# STM32WB07 register map
File version: 1.0
CPU: CM0+ r0p0, little endian, MPU, no FPU, 2 interrupt priority bits
Registers are 32-bit, read-write, reset 0x0 unless marked. A register's access mark holds for its fields unless they carry their own. Offsets are from the block's base; [hi:lo] are bit positions; {n}, {i} and the like mark numbered series; 'fields as' and 'values as' point back to an identical list.

## TIM1
Base 0x40002000
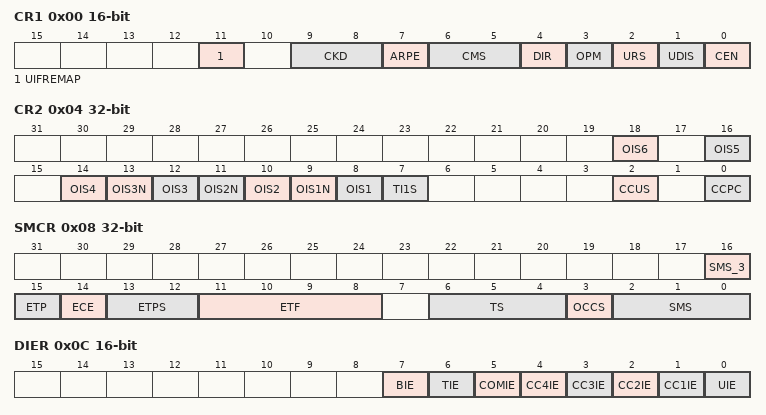
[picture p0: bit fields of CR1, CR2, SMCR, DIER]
0x00 CR1 16-bit (reset mask 0xF)
  [11] UIFREMAP — UIFREMAP: UIF status bit remapping 0: No remapping. UIF status bit is not copied to TIMx_CNT register bit 31. 1: Remapping enabled. UIF status bit is copied to TIMx_CNT register bit 31.
  [9:8] CKD — CKD[1:0]: Clock division This bit-field indicates the division ratio between the timer clock (CK_INT) frequency and the dead-time and sampling clock (tDTS)used by the dead-time generators and the digital filters (TIx), 00: tDTS=tCK_INT 01: tDTS=2*tCK_INT 10: tDTS=4*tCK_INT 11: Reserved, do not program this value
    0=Div1 (t_DTS = t_CK_INT); 1=Div2 (t_DTS = 2 × t_CK_INT); 2=Div4 (t_DTS = 4 × t_CK_INT)
  [7] ARPE — ARPE: Auto-reload preload enable 0: TIMx_ARR register is not buffered 1: TIMx_ARR register is buffered
    0=Disabled (TIMx_APRR register is not buffered); 1=Enabled (TIMx_APRR register is buffered)
  [6:5] CMS — CMS[1:0]: Center-aligned mode selection 00: Edge-aligned mode. The counter counts up or down depending on the direction bit (DIR). 01: Center-aligned mode 1. The counter counts up and down alternatively. Output compare interrupt flags of channels configured in output (CCxS=00 in TIMx_CCMRx register) are set only when the counter is counting down. 10: Center-aligned mode 2. The counter counts up and down alternatively. Output compare interrupt flags of channels configured in output (CCxS=00 in TIMx_CCMRx register) are set only when the counter is counting up. 11: Center-aligned mode 3. The counter counts up and down alternatively. Output compare interrupt flags of channels configured in output (CCxS=00 in TIMx_CCMRx register) are set both when the counter is counting up or down. Note: It is not allowed to switch from edge-aligned mode to center-aligned mode as long as the counter is enabled (CEN=1)
    0=EdgeAligned (The counter counts up or down depending on the direction bit); 1=CenterAligned1 (The counter counts up and down alternatively. Output compare interrupt flags are set only when the counter is counting down.); 2=CenterAligned2 (The counter counts up and down alternatively. Output compare interrupt flags are set only when the counter is counting up.); 3=CenterAligned3 (The counter counts up and down alternatively. Output compare interrupt flags are set both when the counter is counting up or down.)
  [4] DIR — DIR: Direction 0: Counter used as upcounter 1: Counter used as downcounter Note: This bit is read only when the timer is configured in Center-aligned mode or Encoder mode.
    0=Up (Counter used as upcounter); 1=Down (Counter used as downcounter)
  [3] OPM — OPM: One pulse mode 0: Counter is not stopped at update event. 1: Counter stops counting at the next update event (clearing the bit CEN)
    0=Disabled (Counter is not stopped at update event); 1=Enabled (Counter stops counting at the next update event (clearing the CEN bit))
  [2] URS — URS: Update request source This bit is set and cleared by software to select the UEV event sources. 0: Any of the following events generate an update interrupt or DMA request if enabled. These events can be: - Counter overflow/underflow - Setting the UG bit - Update generation through the slave mode controller 1: Only counter overflow/underflow generates an update interrupt or DMA request if enabled.
    0=AnyEvent (Any of counter overflow/underflow, setting UG, or update through slave mode, generates an update interrupt or DMA request); 1=CounterOnly (Only counter overflow/underflow generates an update interrupt or DMA request)
  [1] UDIS — UDIS: Update disable This bit is set and cleared by software to enable/disable UEV event generation. 0: UEV enabled. The Update (UEV) event is generated by one of the following events: - Counter overflow/underflow - Setting the UG bit - Update generation through the slave mode controller Buffered registers are then loaded with their preload values. 1: UEV disabled. The Update event is not generated, shadow registers keep their value (ARR, PSC, CCRx). However the counter and the prescaler are reinitialized if the UG bit is set or if a hardware reset is received from the slave mode controller.
    0=Enabled (Update event enabled); 1=Disabled (Update event disabled)
  [0] CEN — CEN: Counter enable 0: Counter disabled 1: Counter enabled Note: External clock and gated mode can work only if the CEN bit has been previously set by software. However trigger mode can set the CEN bit automatically by hardware.
    0=Disabled (Counter disabled); 1=Enabled (Counter enabled)
0x04 CR2 (reset mask 0xF)
  [2n+7] OIS{n}N (n=1..3) — Output Idle state (OC{n}N output)
    0=Reset (OCxN=0 after a dead-time when MOE=0); 1=Set (OCxN=1 after a dead-time when MOE=0)
  [2n+6] OIS{n} (n=1..6) — Output Idle state (OC{n} output)
    0=Reset (OCx=0 (after a dead-time if OCx(N) is implemented) when MOE=0); 1=Set (OCx=1 (after a dead-time if OCx(N) is implemented) when MOE=0)
  [7] TI1S — TI1S: TI1 selection 0: The TIMx_CH1 pin is connected to TI1 input. 1: The TIMx_CH1, CH2 and CH3 pins are connected to the TI1 input (XOR combination)
  [2] CCUS — Capture/compare control update selection.
    0=Sw (When capture/compare control bits are preloaded (CCPC=1), they are updated by setting the COMG bit only); 1=SwOrEdge (When capture/compare control bits are preloaded (CCPC=1), they are updated by setting the COMG bit or when an rising edge occurs on TRGI)
  [0] CCPC — Capture/compare preloaded control.
    0=NotPreloaded (CCxE, CCxNE and OCxM bits are not preloaded); 1=Preloaded (CCxE, CCxNE and OCxM bits are preloaded)
0x08 SMCR reset not defined
  [16] SMS_3 — SMS[3]: Slave mode selection - bit 3 Refer to SMS description - bits2:0
  [15] ETP — ETP: External trigger polarity This bit selects whether ETR or ETR is used for trigger operations 0: ETR is non-inverted, active at high level or rising edge. 1: ETR is inverted, active at low level or falling edge.
    0=NotInverted (ETR is noninverted, active at high level or rising edge); 1=Inverted (ETR is inverted, active at low level or falling edge)
  [14] ECE — ECE: External clock enable This bit enables External clock mode 2. 0: External clock mode 2 disabled 1: External clock mode 2 enabled. The counter is clocked by any active edge on the ETRF signal. Note: 1: Setting the ECE bit has the same effect as selecting external clock mode 1 with TRGI connected to ETRF (SMS=111 and TS=111). Note: 2: It is possible to simultaneously use external clock mode 2 with the following slave modes: reset mode, gated mode and trigger mode. Nevertheless, TRGI must not be connected to ETRF in this case (TS bits must not be 111). Note: 3: If external clock mode 1 and external clock mode 2 are enabled at the same time, the external clock input is ETRF.
    0=Disabled (External clock mode 2 disabled); 1=Enabled (External clock mode 2 enabled. The counter is clocked by any active edge on the ETRF signal.)
  [13:12] ETPS — ETPS[1:0]: External trigger prescaler External trigger signal ETRP frequency must be at most 1/4 of TIMxCLK frequency. A prescaler can be enabled to reduce ETRP frequency. It is useful when inputting fast external clocks. 00: Prescaler OFF 01: ETRP frequency divided by 2 10: ETRP frequency divided by 4 11: ETRP frequency divided by 8
    0=Div1 (Prescaler OFF); 1=Div2 (ETRP frequency divided by 2); 2=Div4 (ETRP frequency divided by 4); 3=Div8 (ETRP frequency divided by 8)
  [11:8] ETF — ETF[3:0]: External trigger filter This bit-field then defines the frequency used to sample ETRP signal and the length of the digital filter applied to ETRP. The digital filter is made of an event counter in which N events are needed to validate a transition on the output: 0000: No filter, sampling is done at fDTS 0001: fSAMPLING=fCK_INT, N=2 0010: fSAMPLING=fCK_INT, N=4 0011: fSAMPLING=fCK_INT, N=8 0100: fSAMPLING=fDTS/2, N=6 0101: fSAMPLING=fDTS/2, N=8 0110: fSAMPLING=fDTS/4, N=6 0111: fSAMPLING=fDTS/4, N=8 1000: fSAMPLING=fDTS/8, N=6 1001: fSAMPLING=fDTS/8, N=8 1010: fSAMPLING=fDTS/16, N=5 1011: fSAMPLING=fDTS/16, N=6 1100: fSAMPLING=fDTS/16, N=8 1101: fSAMPLING=fDTS/32, N=5 1110: fSAMPLING=fDTS/32, N=6 1111: fSAMPLING=fDTS/32, N=8
    0=No filter, sampling is done at fDTS; 1=FCK_INT_N2 (fSAMPLING=fCK_INT, N=2); 2=FCK_INT_N4 (fSAMPLING=fCK_INT, N=4); 3=FCK_INT_N8 (fSAMPLING=fCK_INT, N=8); 4=FDTS_Div2_N6 (fSAMPLING=fDTS/2, N=6); 5=FDTS_Div2_N8 (fSAMPLING=fDTS/2, N=8); 6=FDTS_Div4_N6 (fSAMPLING=fDTS/4, N=6); 7=FDTS_Div4_N8 (fSAMPLING=fDTS/4, N=8); 8=FDTS_Div8_N6 (fSAMPLING=fDTS/8, N=6); 9=FDTS_Div8_N8 (fSAMPLING=fDTS/8, N=8); 10=FDTS_Div16_N5 (fSAMPLING=fDTS/16, N=5); 11=FDTS_Div16_N6 (fSAMPLING=fDTS/16, N=6); 12=FDTS_Div16_N8 (fSAMPLING=fDTS/16, N=8); 13=FDTS_Div32_N5 (fSAMPLING=fDTS/32, N=5); 14=FDTS_Div32_N6 (fSAMPLING=fDTS/32, N=6); 15=FDTS_Div32_N8 (fSAMPLING=fDTS/32, N=8)
  [6:4] TS — TS[2:0]: Trigger selection This bit-field selects the trigger input to be used to synchronize the counter. 101: Filtered Timer Input 1 (TI1FP1) 110: Filtered Timer Input 2 (TI2FP2) others: Reserved Note: These bits must be changed only when they are not used (e.g. when SMS=000) to avoid wrong edge detections at the transition.
  [3] OCCS — OCCS: OCREF clear selection This bit is used to select the OCREF clear source. 0: OCREF_CLR_INT is connected to the OCREF_CLR input (stuck at 0 so no effect) 1: OCREF_CLR_INT is connected to ETRF
  [2:0] SMS — SMS: Slave mode selection When external signals are selected the active edge of the trigger signal (TRGI) is linked to the polarity selected on the external input (see Input Control register and Control Register description. 0000: Slave mode disabled - if CEN = '1' then the prescaler is clocked directly by the internal clock. 0001: Encoder mode 1 - Counter counts up/down on TI2FP2 edge depending on TI1FP1 level. 0010: Encoder mode 2 - Counter counts up/down on TI1FP1 edge depending on TI2FP2 level. 0011: Encoder mode 3 - Counter counts up/down on both TI1FP1 and TI2FP2 edges depending on the level of the other input. 0100: Reset Mode - Rising edge of the selected trigger input (TRGI) reinitializes the counter and generates an update of the registers. 0101: Gated Mode - The counter clock is enabled when the trigger input (TRGI) is high. The counter stops (but is not reset) as soon as the trigger becomes low. Both start and stop of the counter are controlled. 0110: Trigger Mode - The counter starts at a rising edge of the trigger TRGI (but it is not reset). Only the start of the counter is controlled. 0111: External Clock Mode 1 - Rising edges of the selected trigger (TRGI) clock the counter. 1000: Combined reset + trigger mode - Rising edge of the selected trigger input (TRGI) reinitializes the counter, generates an update of the registers and starts the counter. Codes above 1000: Reserved. Note: The gated mode must not be used if TI1F_ED is selected as the trigger input (TS='100'). Indeed, TI1F_ED outputs 1 pulse for each transition on TI1F, whereas the gated mode checks the level of the trigger signal.
0x0C DIER 16-bit (reset mask 0xF)
  [7] BIE — Break interrupt enable.
    0=Disabled (Break interrupt disabled); 1=Enabled (Break interrupt enabled)
  [6] TIE — TIE: Trigger interrupt enable 0: Trigger interrupt disabled 1: Trigger interrupt enabled
    0=Disabled (Trigger interrupt disabled); 1=Enabled (Trigger interrupt enabled)
  [5] COMIE — COM interrupt enable
    0=Disabled (COM interrupt disabled); 1=Enabled (COM interrupt enabled)
  [n] CC{n}IE (n=1..4) — Capture/Compare {n} interrupt enable
    0=Disabled (CCx interrupt disabled); 1=Enabled (CCx interrupt enabled)
  [0] UIE — UIE: Update interrupt enable 0: Update interrupt disabled 1: Update interrupt enabled
    0=Disabled (Update interrupt disabled); 1=Enabled (Update interrupt enabled)
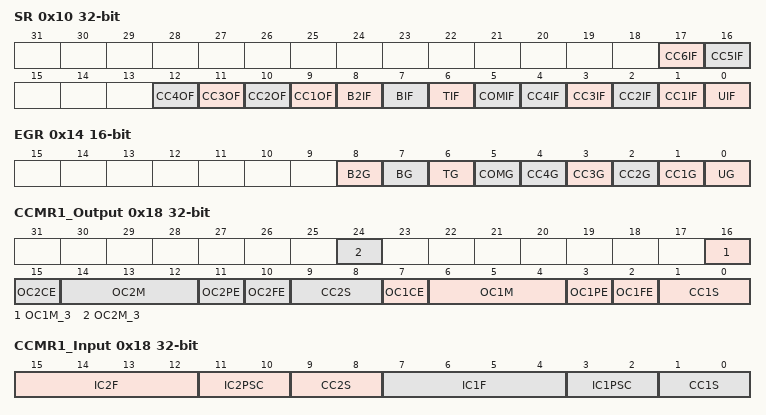
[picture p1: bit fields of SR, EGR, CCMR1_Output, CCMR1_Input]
0x10 SR (reset mask 0xF)
  [17] CC6IF write-0-clears — Compare 6 interrupt flag.
    on read: 0=NoMatch (No campture/compare has been detected); 1=Match (If CC1 is an output: The content of the counter TIMx_CNT matches the content of the TIMx_CCR1 register. If CC1 is an input: The counter value has been captured in TIMx_CCR1 register.) | on write: 0=Clear flag
  [16] CC5IF write-0-clears — Compare 5 interrupt flag.
    values as CC6IF
  [n+8] CC{n}OF (n=1..4) write-0-clears — Capture/Compare {n} overcapture flag
    on read: 0=No overcapture has been detected; 1=Overcapture (The counter value has been captured in TIMx_CCRx register while CCxIF flag was already set) | on write: 0=Clear flag
  [8] B2IF write-0-clears — Break 2 interrupt flag.
    on read: 0=NoTrigger (No break event occurred); 1=Trigger (An active level has been detected on the break 2 input. An interrupt is generated if BIE=1 in the TIMx_DIER register) | on write: 0=Clear flag
  [7] BIF write-0-clears — Break interrupt flag.
    on read: 0=NoTrigger (No break event occurred); 1=Trigger (An active level has been detected on the break input. An interrupt is generated if BIE=1 in the TIMx_DIER register) | on write: 0=Clear flag
  [6] TIF write-0-clears — TIF: Trigger interrupt flag This flag is set by hardware on trigger event (active edge detected on TRGI input when the slave mode controller is enabled in all modes but gated mode. It is set when the counter starts or stops when gated mode is selected. It is cleared by software.. 0: No trigger event occurred. 1: Trigger interrupt pending.
    on read: 0=No trigger event occurred; 1=Trigger interrupt pending | on write: 0=Clear flag
  [5] COMIF write-0-clears — COM interrupt flag.
    on read: 0=No COM event occurred; 1=COM (COM interrupt pending) | on write: 0=Clear flag
  [n] CC{n}IF (n=1..4) write-0-clears — Capture/compare {n} interrupt flag
    values as CC6IF
  [0] UIF write-0-clears — UIF: Update interrupt flag This bit is set by hardware on an update event. It is cleared by software. 0: No update occurred. 1: Update interrupt pending. This bit is set by hardware when the registers are updated: At overflow regarding the repetition counter value (update if repetition counter = 0) and if the UDIS=0 in the TIMx_CR1 register. When CNT is reinitialized by software using the UG bit in TIMx_EGR register, if URS=0 and UDIS=0 in the TIMx_CR1 register.
    on read: 0=NoUpdateOccurred; 1=UpdatePending (Update interrupt pending) | on write: 0=Clear flag
0x14 EGR 16-bit (reset mask 0xF)
  [8] B2G wo — Break 2 generation.
    1=Trigger (A break 2 event is generated. MOE bit is cleared and B2IF flag is set. Related interrupt can occur if enabled)
  [7] BG wo — Break generation.
    1=Trigger (A break event is generated. MOE bit is cleared and BIF flag is set. Related interrupt or DMA transfer can occur if enabled)
  [6] TG wo — TG: Trigger generation This bit is set by software in order to generate an event, it is automatically cleared by hardware. 0: No action 1: The TIF flag is set in TIMx_SR register. Related interrupt can occur if enabled.
    1=Trigger (The TIF flag is set in TIMx_SR register. Related interrupt or DMA transfer can occur if enabled.)
  [5] COMG wo — Capture/compare control update generation.
    1=Trigger (When CCPC bit is set, it allows CCxE, CCxNE and OCxM bits to be updated)
  [n] CC{n}G (n=1..4) wo — Capture/compare {n} generation
    1=Trigger (If CC1 is an output: CC1IF flag is set, Corresponding interrupt or DMA request is sent if enabled. If CC1 is an input: The current value of the counter is captured in TIMx_CCR1 register.)
  [0] UG wo — UG: Update generation This bit can be set by software, it is automatically cleared by hardware. 0: No action. 1: Reinitialize the counter and generates an update of the registers. Note that the prescaler counter is cleared too (anyway the prescaler ratio is not affected).
    1=Update (Re-initializes the timer counter and generates an update of the registers.)
0x18 CCMR1_Output (reset mask 0xF) — CCMR1 register
  [8n+8] OC{n}M_3 (n=1..2) — Output compare {n} mode, bit 3
    0=Normal output compare mode (modes 0-7); 1=Extended output compare mode (modes 7-15)
  [8n-1] OC{n}CE (n=1..2) — Output compare {n} clear enable
    0=Disabled (OCxRef is not affected by the ETRF signal); 1=Enabled (OCxRef is cleared as soon as a High level is detected on ETRF signal)
  [8n-2:8n-4] OC{n}M (n=1..2) — Output compare {n} mode
    0=Frozen (The comparison between the output compare register TIMx_CCRy and the counter TIMx_CNT has no effect on the outputs / OpmMode1: Retriggerable OPM mode 1 - In up-counting mode, the channel is active until a trigger event is detected (on TRGI signal). In down-counting mode, the channel is inactive); 1=ActiveOnMatch (Set channel to active level on match. OCyREF signal is forced high when the counter matches the capture/compare register / OpmMode2: Inversely to OpmMode1); 2=InactiveOnMatch (Set channel to inactive level on match. OCyREF signal is forced low when the counter matches the capture/compare register / Reserved); 3=Toggle (OCyREF toggles when TIMx_CNT=TIMx_CCRy / Reserved); 4=ForceInactive (OCyREF is forced low / CombinedPwmMode1: OCyREF has the same behavior as in PWM mode 1. OCyREFC is the logical OR between OC1REF and OC2REF); 5=ForceActive (OCyREF is forced high / CombinedPwmMode2: OCyREF has the same behavior as in PWM mode 2. OCyREFC is the logical AND between OC1REF and OC2REF); 6=PwmMode1 (In upcounting, channel is active as long as TIMx_CNT<TIMx_CCRy else inactive. In downcounting, channel is inactive as long as TIMx_CNT>TIMx_CCRy else active / AsymmetricPwmMode1: OCyREF has the same behavior as in PWM mode 1. OCyREFC outputs OC1REF when the counter is counting up, OC2REF when it is counting down); 7=PwmMode2 (Inversely to PwmMode1 / AsymmetricPwmMode2: Inversely to AsymmetricPwmMode1)
  [8n-5] OC{n}PE (n=1..2) — Output compare {n} preload enable
    0=Disabled (Preload register on CCRx disabled. New values written to CCRx are taken into account immediately); 1=Enabled (Preload register on CCRx enabled. Preload value is loaded into active register on each update event)
  [8n-6] OC{n}FE (n=1..2) — Output compare {n} fast enable
    0=Disabled (Fast output disabled); 1=Enabled (Fast output enabled)
  [8n-7:8n-8] CC{n}S (n=1..2) — Capture/Compare {n} selection
    0=Output (CCx channel is configured as output)
0x18 CCMR1_Input (reset mask 0xF) (alternate view of CCMR1)
  [9:8] CC2S — CC2S: Capture/Compare 2 selection This bit-field defines the direction of the channel (input/output) as well as the used input. 00: CC2 channel is configured as output 01: CC2 channel is configured as input, IC2 is mapped on TI2 10: CC2 channel is configured as input, IC2 is mapped on TI1 11: CC2 channel is configured as input, IC2 is mapped on TRC. This mode is working only if an internal trigger input is selected through TS bit (TIMx_SMCR register) Note: CC2S bits are writable only when the channel is OFF (CC2E = '0' in TIMx_CCER).
    1=TI2 (CC2 channel is configured as input, IC2 is mapped on TI2); 2=TI1 (CC2 channel is configured as input, IC2 is mapped on TI1); 3=TRC (CC2 channel is configured as input, IC2 is mapped on TRC)
  [8n-1:8n-4] IC{n}F (n=1..2) — Input capture {n} filter
    values as SMCR.ETF
  [8n-5:8n-6] IC{n}PSC (n=1..2) — Input capture {n} prescaler
    0=No prescaler, capture is done each time an edge is detected on the capture input; 1=TwoEvents (Capture is done once every 2 events); 2=FourEvents (Capture is done once every 4 events); 3=EightEvents (Capture is done once every 8 events)
  [1:0] CC1S — CC1S: Capture/Compare 1 Selection This bit-field defines the direction of the channel (input/output) as well as the used input. 00: CC1 channel is configured as output 01: CC1 channel is configured as input, IC1 is mapped on TI1 1x: Reserved Note: CC1S bits are writable only when the channel is OFF (CC1E = '0' in TIMx_CCER).
    1=TI1 (CC1 channel is configured as input, IC1 is mapped on TI1); 2=TI2 (CC1 channel is configured as input, IC1 is mapped on TI2); 3=TRC (CC1 channel is configured as input, IC1 is mapped on TRC)
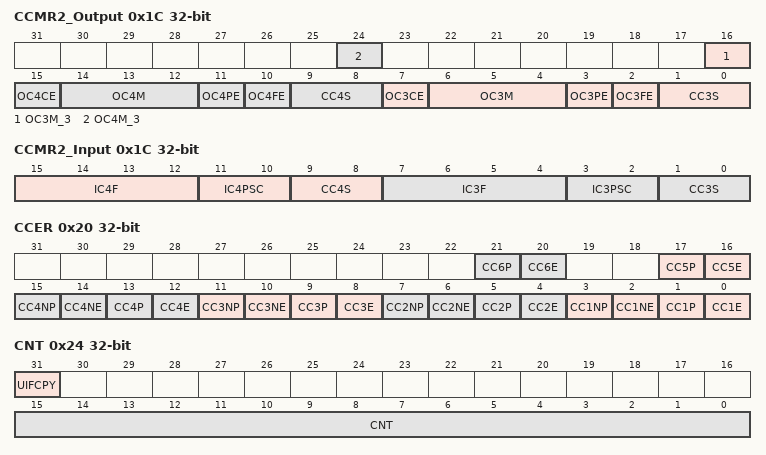
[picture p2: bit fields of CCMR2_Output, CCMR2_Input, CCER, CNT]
0x1C CCMR2_Output (reset mask 0xF) — CCMR2 register
  [8n-8] OC{n}M_3 (n=3..4) — Output compare {n} mode, bit 3
    values as CCMR1_Output.OC1M_3
  [8n-17] OC{n}CE (n=3..4) — Output compare {n} clear enable
    values as CCMR1_Output.OC1CE
  [8n-18:8n-20] OC{n}M (n=3..4) — Output compare {n} mode
    values as CCMR1_Output.OC1M
  [8n-21] OC{n}PE (n=3..4) — Output compare {n} preload enable
    values as CCMR1_Output.OC1PE
  [8n-22] OC{n}FE (n=3..4) — Output compare {n} fast enable
    values as CCMR1_Output.OC1FE
  [8n-23:8n-24] CC{n}S (n=3..4) — Capture/Compare {n} selection
    0=Output (CCx channel is configured as output)
0x1C CCMR2_Input (reset mask 0xF) (alternate view of CCMR2)
  [9:8] CC4S — CC4S: Capture/Compare 4 selection This bit-field defines the direction of the channel (input/output) as well as the used input. 00: CC4 channel is configured as output 01: CC4 channel is configured as input, IC4 is mapped on TI4 10: CC4 channel is configured as input, IC4 is mapped on TI3 11: CC4 channel is configured as input, IC4 is mapped on TRC. This mode is working only if an internal trigger input is selected through TS bit (TIMx_SMCR register) Note: CC4S bits are writable only when the channel is OFF (CC4E = '0' in TIMx_CCER).
    1=TI4 (CC4 channel is configured as input, IC4 is mapped on TI4); 2=TI3 (CC4 channel is configured as input, IC4 is mapped on TI3); 3=TRC (CC4 channel is configured as input, IC4 is mapped on TRC)
  [8n-17:8n-20] IC{n}F (n=3..4) — Input capture {n} filter
    values as SMCR.ETF
  [8n-21:8n-22] IC{n}PSC (n=3..4) — Input capture {n} prescaler
    values as CCMR1_Input.IC1PSC
  [1:0] CC3S — CC3S: Capture/compare 3 selection This bit-field defines the direction of the channel (input/output) as well as the used input. 00: CC3 channel is configured as output 01: CC3 channel is configured as input, IC3 is mapped on TI3 10: CC3 channel is configured as input, IC3 is mapped on TI4 11: CC3 channel is configured as input, IC3 is mapped on TRC. This mode is working only if an internal trigger input is selected through TS bit (TIMx_SMCR register) Note: CC3S bits are writable only when the channel is OFF (CC3E = '0' in TIMx_CCER).
    1=TI3 (CC3 channel is configured as input, IC3 is mapped on TI3); 2=TI4 (CC3 channel is configured as input, IC3 is mapped on TI4); 3=TRC (CC3 channel is configured as input, IC3 is mapped on TRC)
0x20 CCER (reset mask 0xF)
  [4n-1] CC{n}NP (n=1..4) — Capture/Compare {n} output Polarity
    0=ActiveHigh (OCxN active high); 1=ActiveLow (OCxN active low)
  [4n-2] CC{n}NE (n=1..4) — Capture/Compare {n} complementary output enable
    0=Disabled (Complementary output disabled); 1=Enabled (Complementary output enabled)
  [4n-3] CC{n}P (n=1..6) — Capture/Compare {n} output Polarity
    0=RisingEdge (Noninverted/rising edge); 1=FallingEdge (Inverted/falling edge)
  [4n-4] CC{n}E (n=1..6) — Capture/Compare {n} output enable
    0=Disabled (Capture disabled); 1=Enabled (Capture enabled)
0x24 CNT (reset mask 0xF)
  [31] UIFCPY ro — UIFCPY: UIF Copy This bit is a read-only copy of the UIF bit of the TIMx_ISR register. If the UIFREMAP bit in TIMx_CR1 is reset, bit 31 is reserved and read as 0.
  [15:0] CNT — CNT[15:0]: Counter value
0x24 CNT16 16-bit (alternate view of CNT) — 16-bit counter register
  [15:0] CNT — counter value
0x28 PSC 16-bit (reset mask 0xF)
  [15:0] PSC — PSC[15:0]: Prescaler value The counter clock frequency (CK_CNT) is equal to fCK_PSC / (PSC[15:0] + 1). PSC contains the value to be loaded in the active prescaler register at each update event (including when the counter is cleared through UG bit of TIMx_EGR register or through trigger controller when configured in 'reset mode').
0x2C ARR 16-bit reset 0xFFFF
  [15:0] ARR — ARR[15:0]: Prescaler value ARR is the value to be loaded in the actual auto-reload register. Refer to the Section 22.3.1: Time-base unit on page 418 for more details about ARR update and behavior. The counter is blocked while the auto-reload value is null.
0x30 RCR (reset mask 0xF)
  [15:0] REP — REP[7:0]: Repetition counter value These bits allow the user to set-up the update rate of the compare registers (i.e. periodic transfers from preload to active registers) when preload registers are enable, as well as the update interrupt generation rate, if this interrupt is enable. Each time the REP_CNT related downcounter reaches zero, an update event is generated and it restarts counting from REP value. As REP_CNT is reloaded with REP value only at the repetition update event U_RC, any write to the TIMx_RCR register is not taken in account until the next repetition update event. It means in PWM mode (REP+1) corresponds to the number of PWM periods in edge-aligned mode.
{0x30+4i} CCR{i} (i=1..4) 16-bit (reset mask 0xF) — capture/compare register
  [15:0] CCR — Capture/Compare value
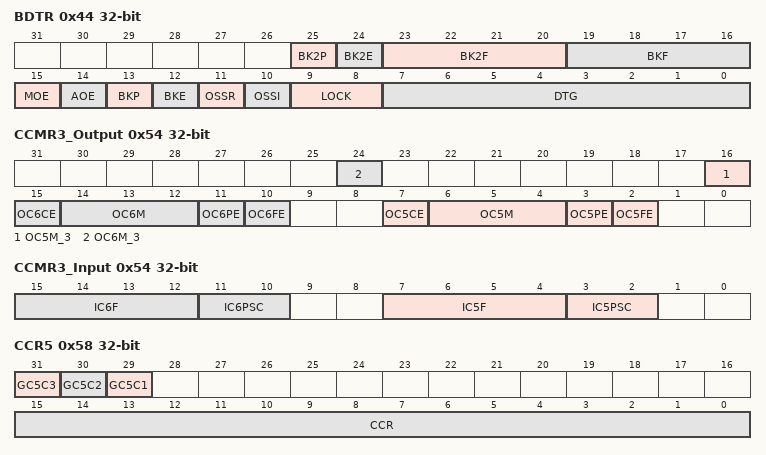
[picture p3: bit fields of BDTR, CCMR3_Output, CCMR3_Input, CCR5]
0x44 BDTR (reset mask 0xF)
  [25] BK2P — Break 2 polarity.
    0=ActiveLow (Break input BRKx is active low); 1=ActiveHigh (Break input BRKx is active high)
  [24] BK2E — Break 2 enable.
    0=Disabled (Break function x disabled); 1=Enabled (Break function x enabled)
  [23:20] BK2F — Break 2 filter.
  [19:16] BKF — Break filter.
  [15] MOE — Main output enable.
    0=DisabledIdle (OC/OCN are disabled or forced idle depending on OSSI); 1=Enabled (OC/OCN are enabled if CCxE/CCxNE are set)
  [14] AOE — Automatic output enable.
    0=Manual (MOE can be set only by software); 1=Automatic (MOE can be set by software or automatically at the next update event (if none of the break inputs BRK and BRK2 is active))
  [13] BKP — Break polarity.
    values as BK2P
  [12] BKE — Break enable.
    values as BK2E
  [11] OSSR — Off-state selection for Run mode.
    0=HiZ (When inactive, OC/OCN outputs are disabled); 1=IdleLevel (When inactive, OC/OCN outputs are enabled with their inactive level)
  [10] OSSI — Off-state selection for Idle mode.
    0=HiZ (When inactive, OC/OCN outputs are disabled); 1=IdleLevel (When inactive, OC/OCN outputs are forced to idle level)
  [9:8] LOCK — Lock configuration.
    0=Off (No bit is write protected); 1=Level1 (Any bits except MOE, OSSR, OSSI and LOCK in TIMx_BDTR register, OISx and OISxN bits in TIMx_CR2 register can no longer be written); 2=Level2 (LOCK Level 1 + CC Polarity bits (CCxP/CCxNP bits in TIMx_CCER register, as long as the related channel is configured in output through the CCxS bits) as well as OSSR and OSSI bits can no longer be written); 3=Level3 (LOCK Level 2 + CC Control bits (OCxM and OCxPE bits in TIMx_CCMRx registers, as long as the related channel is configured in output through the CCxS bits) can no longer be written)
  [7:0] DTG — Deadtime generator setup.
0x54 CCMR3_Output (reset mask 0xF) — CCMR3 register
  [8n-24] OC{n}M_3 (n=5..6) — Output compare {n} mode, bit 3
    values as CCMR1_Output.OC1M_3
  [8n-33] OC{n}CE (n=5..6) — Output compare {n} clear enable
    values as CCMR1_Output.OC1CE
  [8n-34:8n-36] OC{n}M (n=5..6) — Output compare {n} mode
    values as CCMR1_Output.OC1M
  [8n-37] OC{n}PE (n=5..6) — Output compare {n} preload enable
    values as CCMR1_Output.OC1PE
  [8n-38] OC{n}FE (n=5..6) — Output compare {n} fast enable
    values as CCMR1_Output.OC1FE
0x54 CCMR3_Input (reset mask 0xF) (alternate view of CCMR3)
  [8n-33:8n-36] IC{n}F (n=5..6) — Input capture {n} filter
    values as SMCR.ETF
  [8n-37:8n-38] IC{n}PSC (n=5..6) — Input capture {n} prescaler
    values as CCMR1_Input.IC1PSC
0x58 CCR5 (reset mask 0xF) — capture/compare register
  [31] GC5C3 — Group channel 5 and channel 3 distortion on channel 3 output: 0: No effect of OC5REF on OC3REFC 1: OC3REFC is the logical AND of OC3REFC and OC5REF This bit can either have immediate effect or be preloaded and taken into account after an update event (if preload feature is selected in TIMxCCMR2). Note: It is also possible to apply this distortion on combined PWM signals.
  [30] GC5C2 — Group channel 5 and channel 2 distortion on channel 2 output: 0: No effect of OC5REF on OC2REFC 1: OC2REFC is the logical AND of OC2REFC and OC5REF This bit can either have immediate effect or be preloaded and taken into account after an update event (if preload feature is selected in TIMxCCMR1). Note: It is also possible to apply this distortion on combined PWM signals.
  [29] GC5C1 — Group channel 5 and channel 1 distortion on channel 1 output: 0: No effect of OC5REF on OC1REFC5 1: OC1REFC is the logical AND of OC1REFC and OC5REF This bit can either have immediate effect or be preloaded and taken into account after an update event (if preload feature is selected in TIMxCCMR1). Note: It is also possible to apply this distortion on combined PWM signals.
  [15:0] CCR — Capture/Compare value
0x5C CCR6 16-bit (reset mask 0xF) — capture/compare register
  [15:0] CCR — Capture/Compare value
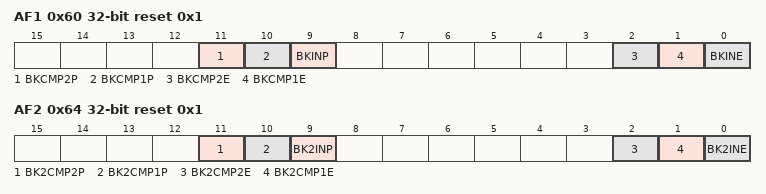
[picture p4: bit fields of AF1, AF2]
0x60 AF1 reset 0x1 (reset mask 0xF)
  [11] BKCMP2P — BRK COMP2 input polarity
  [10] BKCMP1P — BRK COMP1 input polarity
  [9] BKINP — BRK BKIN input polarity
  [2] BKCMP2E — BRK COMP2 enable
  [1] BKCMP1E — BRK COMP1 enable
  [0] BKINE — BRK BKIN input enable
0x64 AF2 reset 0x1 (reset mask 0xF)
  [11] BK2CMP2P — BRK2 COMP2 input polarity.
  [10] BK2CMP1P — BRK2 COMP1 input polarity.
  [9] BK2INP — BRK2 BKIN2 input polarity
  [2] BK2CMP2E — BRK2 COMP2 enable.
  [1] BK2CMP1E — BRK2 COMP1 enable.
  [0] BK2INE — BRK2 BKIN input enable.
